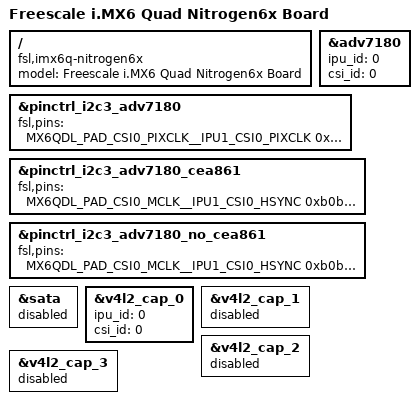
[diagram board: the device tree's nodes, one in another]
/*
 * Copyright 2013-2016 Boundary Devices, Inc.
 * Copyright 2012 Freescale Semiconductor, Inc.
 * Copyright 2011 Linaro Ltd.
 *
 * The code contained herein is licensed under the GNU General Public
 * License. You may obtain a copy of the GNU General Public License
 * Version 2 or later at the following locations:
 *
 * http://www.opensource.org/licenses/gpl-license.html
 * http://www.gnu.org/copyleft/gpl.html
 */

/dts-v1/;

#include <dt-bindings/interrupt-controller/irq.h>
#include "imx6q.dtsi"
#include "imx6qdl-nitrogen6x.dtsi"

/ {
	model = "Freescale i.MX6 Quad Nitrogen6x Board";
	compatible = "fsl,imx6q-nitrogen6x", "fsl,imx6q";
};

&adv7180 {
	ipu_id = <0>;
	csi_id = <0>;
};

/*
&pinctrl_i2c3_adv7180 {
	fsl,pins = <
		MX6QDL_PAD_EIM_A16__IPU2_CSI1_PIXCLK     0xb0b1
		MX6QDL_PAD_EIM_A17__IPU2_CSI1_DATA12  	 0xb0b1
		MX6QDL_PAD_EIM_A18__IPU2_CSI1_DATA13   	 0xb0b1
		MX6QDL_PAD_EIM_A19__IPU2_CSI1_DATA14     0xb0b1
		MX6QDL_PAD_EIM_A20__IPU2_CSI1_DATA15     0xb0b1
		MX6QDL_PAD_EIM_A21__IPU2_CSI1_DATA16     0xb0b1
		MX6QDL_PAD_EIM_A22__IPU2_CSI1_DATA17     0xb0b1
		MX6QDL_PAD_EIM_A23__IPU2_CSI1_DATA18     0xb0b1
		MX6QDL_PAD_EIM_A24__IPU2_CSI1_DATA19     0xb0b1
       >;
};

&pinctrl_i2c3_adv7180_cea861 {
	fsl,pins = <
		MX6QDL_PAD_EIM_DA11__IPU2_CSI1_HSYNC	0xb0b1
		MX6QDL_PAD_EIM_DA12__IPU2_CSI1_VSYNC	0xb0b1
	>;
};
&pinctrl_i2c3_adv7180_no_cea861 {
	fsl,pins = <
			MX6QDL_PAD_EIM_DA11__IPU2_CSI1_HSYNC     0xb0b1
			MX6QDL_PAD_EIM_DA12__IPU2_CSI1_VSYNC     0xb0b1
		>;
};
*/

//CSI0
&pinctrl_i2c3_adv7180 {
	fsl,pins = <
		MX6QDL_PAD_CSI0_PIXCLK__IPU1_CSI0_PIXCLK     0xb0b1
		MX6QDL_PAD_CSI0_DAT12__IPU1_CSI0_DATA12  	 0xb0b1
		MX6QDL_PAD_CSI0_DAT13__IPU1_CSI0_DATA13   	 0xb0b1
		MX6QDL_PAD_CSI0_DAT14__IPU1_CSI0_DATA14     0xb0b1
		MX6QDL_PAD_CSI0_DAT15__IPU1_CSI0_DATA15     0xb0b1
		MX6QDL_PAD_CSI0_DAT16__IPU1_CSI0_DATA16     0xb0b1
		MX6QDL_PAD_CSI0_DAT17__IPU1_CSI0_DATA17     0xb0b1
		MX6QDL_PAD_CSI0_DAT18__IPU1_CSI0_DATA18     0xb0b1
		MX6QDL_PAD_CSI0_DAT19__IPU1_CSI0_DATA19     0xb0b1
       >;
};

&pinctrl_i2c3_adv7180_cea861 {
	fsl,pins = <
		MX6QDL_PAD_CSI0_MCLK__IPU1_CSI0_HSYNC	0xb0b1
		MX6QDL_PAD_CSI0_VSYNC__IPU1_CSI0_VSYNC	0xb0b1
	>;
};
&pinctrl_i2c3_adv7180_no_cea861 {
	fsl,pins = <
			MX6QDL_PAD_CSI0_MCLK__IPU1_CSI0_HSYNC     0xb0b1
			MX6QDL_PAD_CSI0_VSYNC__IPU1_CSI0_VSYNC     0xb0b1
		>;
};

&sata {
	status = "disabled";
};

&v4l2_cap_0 {
	ipu_id = <0>;
	csi_id = <0>;
};

/* ov5640_mipi */
&v4l2_cap_1 {
	status = "disabled";
};

/* adv7180, ov5640 */
&v4l2_cap_2 {
	status = "disabled";
};

&v4l2_cap_3 {
	status = "disabled";
};
